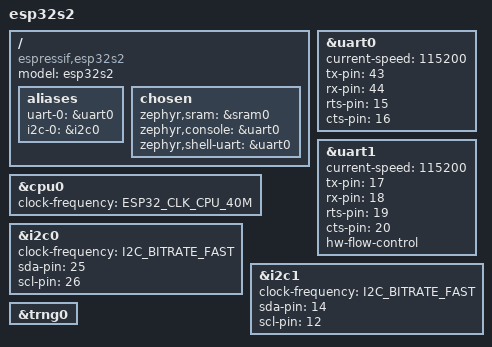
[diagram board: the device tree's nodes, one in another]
/*
 * Copyright (c) 2020 Intel Corporation.
 *
 * SPDX-License-Identifier: Apache-2.0
 */
/dts-v1/;

#include <espressif/esp32s2.dtsi>

/ {
	model = "esp32s2";
	compatible = "espressif,esp32s2";

	aliases {
		uart-0 = &uart0;
		i2c-0 = &i2c0;
	};

	chosen {
		zephyr,sram = &sram0;
		zephyr,console = &uart0;
		zephyr,shell-uart = &uart0;
	};
};

&cpu0 {
	clock-frequency = <ESP32_CLK_CPU_40M>;
};

&uart0 {
	status = "okay";
	current-speed = <115200>;
	tx-pin = <43>;
	rx-pin = <44>;
	rts-pin = <15>;
	cts-pin = <16>;
};

&uart1 {
	current-speed = <115200>;
	tx-pin = <17>;
	rx-pin = <18>;
	rts-pin = <19>;
	cts-pin = <20>;
	hw-flow-control;
};

&i2c0 {
	status = "okay";
	clock-frequency = <I2C_BITRATE_FAST>;
	sda-pin = <25>;
	scl-pin = <26>;
};

&i2c1 {
	clock-frequency = <I2C_BITRATE_FAST>;
	sda-pin = <14>;
	scl-pin = <12>;
};

&trng0 {
	status = "okay";
};
